AUTOSAR XML (schema 4-0-3)
package /ComponentTypes
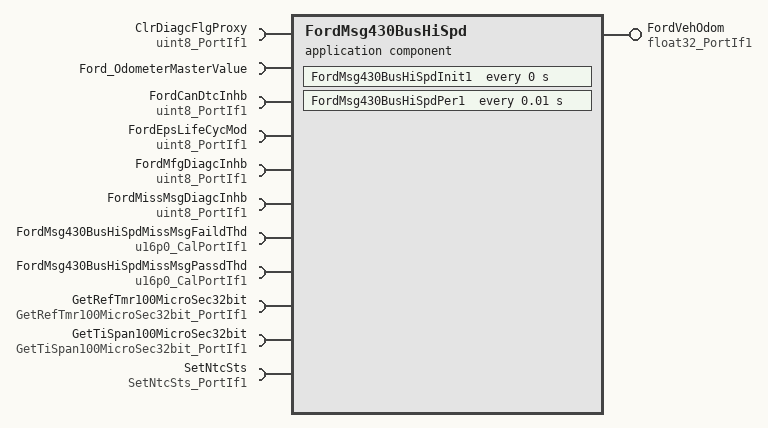
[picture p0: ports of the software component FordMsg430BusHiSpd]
  application sw component type FordMsg430BusHiSpd  # The purpose of the Ford Message 430 Bus High Speed function is to provide the Electric Power Steeringsystem with vehicle odometer, climate, and Trailer Back Up Assist signals from CAN. The Ford Message430 function will perform the missing message and signal invalid diagnostics as well as provide avalidity signal for the signal values and received message.
    provide port FordVehOdom: nonqueued-sender-com-spec{data-element=Val, init-value=0}, provided-interface=float32_PortIf1  # Ford_OdometerMasterValue is assigned to Ford Vehicle Odometer to be used by EPS
    11 x require port:
      ClrDiagcFlgProxy: nonqueued-receiver-com-spec{data-element=Val, filter=data-filter-type=ALWAYS, init-value=0}, required-interface=uint8_PortIf1  # When ClrDiagcFlgProxy is True, Diagnostic test is performed
      Ford_OdometerMasterValue: nonqueued-receiver-com-spec{data-element=Ford_OdometerMasterValue, filter=data-filter-type=ALWAYS, init-value=0}, required-interface=Ford_OdometerMasterValue  # It is a message signal which is received from CAN bus which will be processed and used in EPS
      FordCanDtcInhb: nonqueued-receiver-com-spec{data-element=Val, filter=data-filter-type=ALWAYS, init-value=1}, required-interface=uint8_PortIf1  # This signal should be set to 0 in order to Test NTC
      FordEpsLifeCycMod: nonqueued-receiver-com-spec{data-element=Val, filter=data-filter-type=ALWAYS, init-value=0}, required-interface=uint8_PortIf1  # This signal is used to decide calibratable value or some fixed value to FAIL the NTC
      FordMfgDiagcInhb: nonqueued-receiver-com-spec{data-element=Val, filter=data-filter-type=ALWAYS, init-value=0}, required-interface=uint8_PortIf1  # When Manufacturing Diagnostic Inhibit is False, Diagnostic test is performed
      FordMissMsgDiagcInhb: nonqueued-receiver-com-spec{data-element=Val, filter=data-filter-type=ALWAYS, init-value=0}, required-interface=uint8_PortIf1  # When MissMsgDiagcInhb is FALSE, Diagnostic test is performed
      FordMsg430BusHiSpdMissMsgFaildThd: parameter-require-com-spec{init-value=5000, parameter=Val}, required-interface=u16p0_CalPortIf1  # Threshold to Reset the Missing message NTC
      FordMsg430BusHiSpdMissMsgPassdThd: parameter-require-com-spec{init-value=0, parameter=Val}, required-interface=u16p0_CalPortIf1  # Threshold to Reset the Missing message NTC
      GetRefTmr100MicroSec32bit: client-com-spec=Oper, required-interface=GetRefTmr100MicroSec32bit_PortIf1  # It captures simulation time fromthe SimnTi value obtained at root layer of model and gives the RefTmr
      GetTiSpan100MicroSec32bit: client-com-spec=Oper, required-interface=GetTiSpan100MicroSec32bit_PortIf1  # It Captures simulation time from SimnTi value, handles counter wrapping, and subtracts RefTmr, provides the TiSpan
      SetNtcSts: client-com-spec=Oper, required-interface=SetNtcSts_PortIf1  # Returns the NTC Qualifier status
    behavior FordMsg430BusHiSpd_InternalBehavior
      ar-typed-per-instance-memorys:
        6 x data, all with sw-calibration-access=READ-ONLY:
          ClrDiagcFlgProxyPrev: type=uint8  # Clear Diagnostics Flag Proxy Previous
          FordVehMsg430Miss: type=boolean  # Flag for missing message diagnostics, it is true when message is missing
          FordVehMsg430Rxd: type=boolean  # Flag for missing message diagnostics, it is true when message is received
          FordVehOdomPrev: type=float32  # Previous Value for Ford Vehicle Odometer
          MissMsgFaildRefTi: type=uint32  # Timer for missing message will increment or reset based on the conditions
          MissMsgPassdRefTi: type=uint32  # Timer for missing message will increment or reset based on the conditions
      timing event FordMsg430BusHiSpd_InitEvent: start-on-event=FordMsg430BusHiSpdInit1, period=0
      timing event TMT_FordMsg430BusHiSpdPer1: start-on-event=FordMsg430BusHiSpdPer1, period=0.01
      port-api-options:
        enable-take-address=false, indirect-api=false, port=Ford_OdometerMasterValue
        enable-take-address=false, indirect-api=false, port=FordEpsLifeCycMod
        enable-take-address=false, indirect-api=false, port=SetNtcSts
      runnable FordMsg430BusHiSpdInit1  # Initialization Runnable
        sync call SC_GetRefTmr100MicroSec32bit_Oper: operation=GetRefTmr100MicroSec32bit.Oper, timeout=0
      runnable FordMsg430BusHiSpdPer1  # Periodic Runnable at 10 millisecond
        data-receive-point-by-arguments:
          6 x access:
            REC_ClrDiagcFlgProxy_Val: accessed-variable=ClrDiagcFlgProxy.Val
            REC_Ford_OdometerMasterValue_Ford_OdometerMasterValue: accessed-variable=Ford_OdometerMasterValue.Ford_OdometerMasterValue
            REC_FordCanDtcInhb_Val: accessed-variable=FordCanDtcInhb.Val
            REC_FordEpsLifeCycMod_Val: accessed-variable=FordEpsLifeCycMod.Val
            REC_FordMfgDiagcInhb_Val: accessed-variable=FordMfgDiagcInhb.Val
            REC_FordMissMsgDiagcInhb_Val: accessed-variable=FordMissMsgDiagcInhb.Val
        data-send-points:
          access SEND_FordVehOdom_Val: accessed-variable=FordVehOdom.Val
        sync call SC_GetRefTmr100MicroSec32bit_Oper: operation=GetRefTmr100MicroSec32bit.Oper, timeout=0
        sync call SC_GetTiSpan100MicroSec32bit_Oper: operation=GetTiSpan100MicroSec32bit.Oper, timeout=0
        sync call SC_SetNtcSts_Oper: operation=SetNtcSts.Oper, timeout=0
  swc implementation FordMsg430BusHiSpd_Implementation: behavior=FordMsg430BusHiSpd_InternalBehavior
    code-descriptors:
      code Default: artifact-descriptors=autosar-engineering-object={short-label=Default, category=SWSRC}
